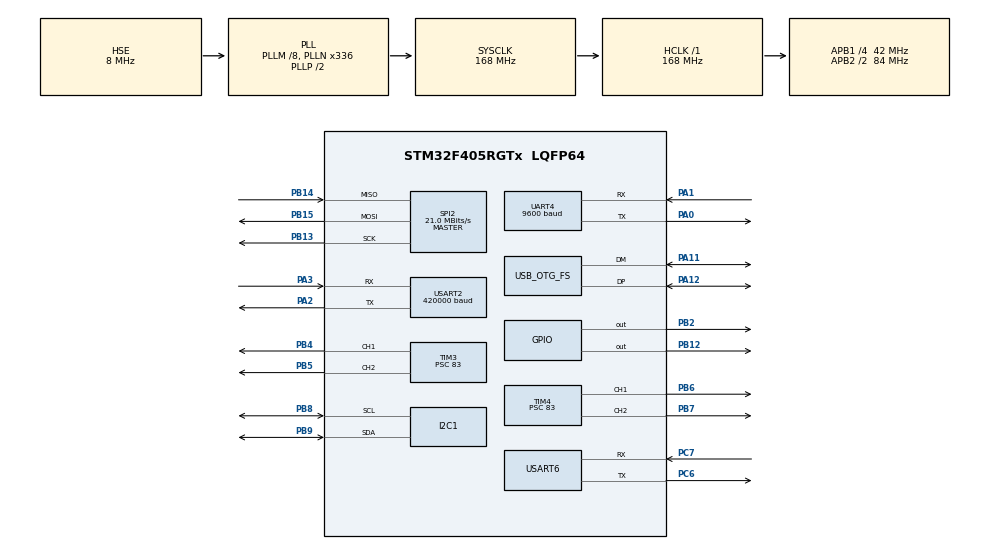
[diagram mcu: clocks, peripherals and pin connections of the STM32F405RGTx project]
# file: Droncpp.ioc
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Dma.Request0=UART4_TX
Dma.Request1=USART2_RX
Dma.Request2=USART2_TX
Dma.UART4_TX.0.Direction=DMA_MEMORY_TO_PERIPH
Dma.UART4_TX.0.FIFOMode=DMA_FIFOMODE_DISABLE
Dma.UART4_TX.0.Instance=DMA1_Stream4
Dma.UART4_TX.0.MemDataAlignment=DMA_MDATAALIGN_BYTE
Dma.UART4_TX.0.MemInc=DMA_MINC_ENABLE
Dma.UART4_TX.0.Mode=DMA_NORMAL
Dma.UART4_TX.0.PeriphDataAlignment=DMA_PDATAALIGN_BYTE
Dma.UART4_TX.0.PeriphInc=DMA_PINC_DISABLE
Dma.UART4_TX.0.Priority=DMA_PRIORITY_LOW
Dma.USART2_RX.1.Direction=DMA_PERIPH_TO_MEMORY
Dma.USART2_RX.1.FIFOMode=DMA_FIFOMODE_DISABLE
Dma.USART2_RX.1.Instance=DMA1_Stream5
Dma.USART2_RX.1.MemDataAlignment=DMA_MDATAALIGN_BYTE
Dma.USART2_RX.1.MemInc=DMA_MINC_ENABLE
Dma.USART2_RX.1.Mode=DMA_CIRCULAR
Dma.USART2_RX.1.PeriphDataAlignment=DMA_PDATAALIGN_BYTE
Dma.USART2_RX.1.PeriphInc=DMA_PINC_DISABLE
Dma.USART2_RX.1.Priority=DMA_PRIORITY_VERY_HIGH
Dma.USART2_TX.2.Direction=DMA_MEMORY_TO_PERIPH
Dma.USART2_TX.2.FIFOMode=DMA_FIFOMODE_DISABLE
Dma.USART2_TX.2.Instance=DMA1_Stream6
Dma.USART2_TX.2.MemDataAlignment=DMA_MDATAALIGN_BYTE
Dma.USART2_TX.2.MemInc=DMA_MINC_ENABLE
Dma.USART2_TX.2.Mode=DMA_CIRCULAR
Dma.USART2_TX.2.PeriphDataAlignment=DMA_PDATAALIGN_BYTE
Dma.USART2_TX.2.PeriphInc=DMA_PINC_DISABLE
Dma.USART2_TX.2.Priority=DMA_PRIORITY_VERY_HIGH
I2C1.I2C_Mode=I2C_Fast
Mcu.Family=STM32F4
Mcu.Name=STM32F405RGTx
Mcu.Package=LQFP64
NVIC.DMA1_Stream4_IRQn=true\:0\:0\:false\:false\:true\:false\:true\:true
NVIC.DMA1_Stream5_IRQn=true\:0\:0\:false\:false\:true\:false\:true\:true
NVIC.DMA1_Stream6_IRQn=true\:0\:0\:false\:false\:true\:false\:true\:true
NVIC.OTG_FS_IRQn=true\:0\:0\:false\:false\:true\:false\:true\:true
NVIC.PriorityGroup=NVIC_PRIORITYGROUP_4
NVIC.UART4_IRQn=true\:0\:0\:false\:false\:true\:true\:true\:true
NVIC.USART2_IRQn=true\:0\:0\:false\:false\:true\:true\:true\:true
NVIC.USART6_IRQn=true\:0\:0\:false\:false\:true\:true\:true\:true
PA0-WKUP.Mode=Asynchronous
PA0-WKUP.Signal=UART4_TX
PA1.Mode=Asynchronous
PA1.Signal=UART4_RX
PA11.Mode=Device_Only
PA11.Signal=USB_OTG_FS_DM
PA12.Mode=Device_Only
PA12.Signal=USB_OTG_FS_DP
PA13.Mode=Serial_Wire
PA13.Signal=SYS_JTMS-SWDIO
PA14.Mode=Serial_Wire
PA14.Signal=SYS_JTCK-SWCLK
PA2.Mode=Asynchronous
PA2.Signal=USART2_TX
PA3.Mode=Asynchronous
PA3.Signal=USART2_RX
PB12.Signal=GPIO_Output
PB13.Mode=Full_Duplex_Master
PB13.Signal=SPI2_SCK
PB14.Mode=Full_Duplex_Master
PB14.Signal=SPI2_MISO
PB15.Mode=Full_Duplex_Master
PB15.Signal=SPI2_MOSI
PB2.Signal=GPIO_Output
PB4.Signal=S_TIM3_CH1
PB5.Signal=S_TIM3_CH2
PB6.Signal=S_TIM4_CH1
PB7.Signal=S_TIM4_CH2
PB8.Mode=I2C
PB8.Signal=I2C1_SCL
PB9.Mode=I2C
PB9.Signal=I2C1_SDA
PC6.Mode=Asynchronous
PC6.Signal=USART6_TX
PC7.Mode=Asynchronous
PC7.Signal=USART6_RX
PH0-OSC_IN.Mode=HSE-External-Oscillator
PH0-OSC_IN.Signal=RCC_OSC_IN
PH1-OSC_OUT.Mode=HSE-External-Oscillator
PH1-OSC_OUT.Signal=RCC_OSC_OUT
ProjectManager.HeapSize=0x200
ProjectManager.StackSize=0x400
ProjectManager.TargetToolchain=STM32CubeIDE
RCC.48MHZClocksFreq_Value=48000000
RCC.AHBFreq_Value=168000000
RCC.APB1CLKDivider=RCC_HCLK_DIV4
RCC.APB1Freq_Value=42000000
RCC.APB1TimFreq_Value=84000000
RCC.APB2CLKDivider=RCC_HCLK_DIV2
RCC.APB2Freq_Value=84000000
RCC.APB2TimFreq_Value=168000000
RCC.CortexFreq_Value=168000000
RCC.HCLKFreq_Value=168000000
RCC.HSE_VALUE=8000000
RCC.HSI_VALUE=16000000
RCC.LSE_VALUE=32768
RCC.PLLM=8
RCC.PLLN=336
RCC.PLLQ=7
RCC.SYSCLKFreq_VALUE=168000000
RCC.SYSCLKSource=RCC_SYSCLKSOURCE_PLLCLK
RCC.VCOOutputFreq_Value=336000000
SH.S_TIM3_CH1.0=TIM3_CH1,PWM Generation1 CH1
SH.S_TIM3_CH2.0=TIM3_CH2,PWM Generation2 CH2
SH.S_TIM4_CH1.0=TIM4_CH1,PWM Generation1 CH1
SH.S_TIM4_CH2.0=TIM4_CH2,PWM Generation2 CH2
SPI2.BaudRatePrescaler=SPI_BAUDRATEPRESCALER_2
SPI2.CalculateBaudRate=21.0 MBits/s
SPI2.Direction=SPI_DIRECTION_2LINES
SPI2.Mode=SPI_MODE_MASTER
SPI2.VirtualType=VM_MASTER
TIM3.Channel-PWM\ Generation1\ CH1=TIM_CHANNEL_1
TIM3.Channel-PWM\ Generation2\ CH2=TIM_CHANNEL_2
TIM3.OC1Preload_PWM=DISABLE
TIM3.OC2Preload_PWM=DISABLE
TIM3.OCMode_PWM-PWM\ Generation1\ CH1=TIM_OCMODE_PWM1
TIM3.OCMode_PWM-PWM\ Generation2\ CH2=TIM_OCMODE_PWM1
TIM3.OCPolarity_1=TIM_OCPOLARITY_HIGH
TIM3.OCPolarity_2=TIM_OCPOLARITY_HIGH
TIM3.Period=19999
TIM3.Prescaler=83
TIM4.Channel-PWM\ Generation1\ CH1=TIM_CHANNEL_1
TIM4.Channel-PWM\ Generation2\ CH2=TIM_CHANNEL_2
TIM4.OC1Preload_PWM=DISABLE
TIM4.OC2Preload_PWM=DISABLE
TIM4.OCPolarity_1=TIM_OCPOLARITY_HIGH
TIM4.OCPolarity_2=TIM_OCPOLARITY_HIGH
TIM4.Period=19999
TIM4.Prescaler=83
UART4.BaudRate=9600
UART4.VirtualMode=Asynchronous
USART2.BaudRate=420000
USART2.VirtualMode=VM_ASYNC
USART6.VirtualMode=VM_ASYNC
USB_DEVICE.CLASS_NAME_FS=CDC
USB_DEVICE.VirtualMode-CDC_FS=Cdc
USB_DEVICE.VirtualModeFS=Cdc_FS
USB_OTG_FS.VirtualMode=Device_Only
VP_TIM3_VS_ClockSourceINT.Mode=Internal
VP_TIM4_VS_ClockSourceINT.Mode=Internal
VP_USB_DEVICE_VS_USB_DEVICE_CDC_FS.Mode=CDC_FS
board=custom

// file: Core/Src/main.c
/* USER CODE BEGIN Header */
/**
  ******************************************************************************
  * @file           : main.c
  * @brief          : Main program body
  ******************************************************************************
  * @attention
  *
  * Copyright (c) 2026 STMicroelectronics.
  * All rights reserved.
  *
  * This software is licensed under terms that can be found in the LICENSE file
  * in the root directory of this software component.
  * If no LICENSE file comes with this software, it is provided AS-IS.
  *
  ******************************************************************************
  */
/* USER CODE END Header */
#include "main.h"
#include "usb_device.h"

/* USER CODE BEGIN Includes */
#include "usbd_cdc_if.h"
//#include "mpu6500.hpp"
//#include "qmc5883p.hpp"
//#include "gnss.hpp"
//#include "mtf02.hpp"
//#include "crsf.hpp"
#include "puente.h"
/* USER CODE END Includes */

I2C_HandleTypeDef hi2c1;

SPI_HandleTypeDef hspi2;

TIM_HandleTypeDef htim3;
TIM_HandleTypeDef htim4;

UART_HandleTypeDef huart4;
UART_HandleTypeDef huart2;
UART_HandleTypeDef huart6;
DMA_HandleTypeDef hdma_uart4_tx;
DMA_HandleTypeDef hdma_usart2_rx;
DMA_HandleTypeDef hdma_usart2_tx;

/* USER CODE BEGIN PV */
//static MPU6500 imu(&hspi2);
//static QMC5883 mag(&hi2c1);
//static Gnss gps(&huart4);
//static MTF01 flow(&huart6);
//static CRSF_Radio radioData;
//static CRSF radio(&huart2);
/* USER CODE END PV */

void SystemClock_Config(void);
static void MX_GPIO_Init(void);
static void MX_DMA_Init(void);
static void MX_SPI2_Init(void);
static void MX_I2C1_Init(void);
static void MX_UART4_Init(void);
static void MX_USART6_UART_Init(void);
static void MX_USART2_UART_Init(void);
static void MX_TIM3_Init(void);
static void MX_TIM4_Init(void);

int main(void)
{

  /* MCU Configuration--------------------------------------------------------*/

  /* Reset of all peripherals, Initializes the Flash interface and the Systick. */
  HAL_Init();

  /* Configure the system clock */
  SystemClock_Config();

  /* Initialize all configured peripherals */
  MX_GPIO_Init();
  MX_DMA_Init();
  MX_SPI2_Init();
  MX_USB_DEVICE_Init();
  MX_I2C1_Init();
  MX_UART4_Init();
  MX_USART6_UART_Init();
  MX_USART2_UART_Init();
  MX_TIM3_Init();
  MX_TIM4_Init();
  /* USER CODE BEGIN 2 */
  //imu.Init();
  //imu.CalibrateGyro();
  //imu.CalibrateAccel();
  //mag.Init();
  //gps.Init();
  //gps.SetMode(GnssMode::Stationary);
  //HAL_Delay(250);
  //flow.Init();
  //radio.Init(&radioData);

  HAL_TIM_PWM_Start(&htim3, TIM_CHANNEL_1);
  HAL_TIM_PWM_Start(&htim3, TIM_CHANNEL_2);
  HAL_TIM_PWM_Start(&htim4, TIM_CHANNEL_1);
  HAL_TIM_PWM_Start(&htim4, TIM_CHANNEL_2);

  //__HAL_TIM_SET_COMPARE(&htim3, TIM_CHANNEL_1, 1900);
  //__HAL_TIM_SET_COMPARE(&htim3, TIM_CHANNEL_2, 1900);
  //__HAL_TIM_SET_COMPARE(&htim4, TIM_CHANNEL_1, 1900);
  //__HAL_TIM_SET_COMPARE(&htim4, TIM_CHANNEL_2, 1900);
  //HAL_Delay(3000);
  __HAL_TIM_SET_COMPARE(&htim3, TIM_CHANNEL_1, 1100);
  __HAL_TIM_SET_COMPARE(&htim3, TIM_CHANNEL_2, 1100);
  __HAL_TIM_SET_COMPARE(&htim4, TIM_CHANNEL_1, 1100);
  __HAL_TIM_SET_COMPARE(&htim4, TIM_CHANNEL_2, 1100);

  //App_Init();

  /* USER CODE END 2 */

  /* Infinite loop */
  while (1)
  {

    /* USER CODE BEGIN 3 */
	  //App_Loop();
	  	  /*imu.Process();
	      const MPU6500_Data &d = imu.GetData();

	      static char msg[150];    imu.Process();
    mag.Process();
    mag.ComputeHeading(imu.GetData().roll, imu.GetData().pitch);
    radio.Process();

    static uint32_t lastGpsUpdate = 0;
    if(HAL_GetTick() - lastGpsUpdate >= 200)
    {
        lastGpsUpdate = HAL_GetTick();
        gps.Update();
        // impresión...
    }
    // resto de la lógica de impresión...
	      int len = snprintf(msg, sizeof(msg),"AX:%.2f AY:%.2f AZ:%.2f\r\n"
											  "GX:%.2f GY:%.2f GZ:%.2f \r\n"
	    		  	  	  	  	  	  	  	  "Roll:%.2f Pitch:%.2f\r\n",
											  d.ax, d.ay, d.az, d.gx, d.gy, d.gz, d.roll, d.pitch);

	      CDC_Transmit_FS((uint8_t*)msg, len);
	      HAL_Delay(100);
	      mag.Process();         // usa el roll/pitch fresco del gyro
	      mag.ComputeHeading(imu.GetData().roll, imu.GetData().pitch);   // calcula heading aparte

	      const QMC5883Data &d = mag.GetData();

	      static char msg[100];
	      int len = snprintf(msg, sizeof(msg),
	          "MX:%.2f MY:%.2f MZ:%.2f Heading:%.2f\r\n",
	          d.mx, d.my, d.mz, d.heading);

	      CDC_Transmit_FS((uint8_t*)msg, len);
	      HAL_Delay(100);
	      static uint32_t lastGpsUpdate = 0;
	          if(HAL_GetTick() - lastGpsUpdate >= 200)
	          {
	              lastGpsUpdate = HAL_GetTick();
	              gps.Update();

	              const GnssData &d = gps.GetData();
	              static char msg[300];
	              int len = snprintf(msg, sizeof(msg),
	                  "GPS\r\n"
	                  "Day: %d-%d-%d\r\n"
	                  "Time: %d:%d:%d\r\n"
	                  "Status of fix: %d\r\n"
	                  "Sat used: %d  Sat count: %d\r\n"
	                  "Lat: %f  Lon: %f\r\n"
	                  "Height ellip.(m): %f  Height MSL(m): %f\r\n"
	                  "Ground Speed(2D): %ld\r\n",
	                  d.day, d.month, d.year,
	                  d.hour, d.min, d.sec,
	                  d.fixType,
	                  d.numSV, d.satCount,
	                  d.fLat, d.fLon,
	                  static_cast<float>(d.height) / 1000.0f,
	                  static_cast<float>(d.hMSL) / 1000.0f,
	                  d.gSpeed);
	              CDC_Transmit_FS((uint8_t*)msg, len);
	          }
	      const MTF01_Data &d = flow.GetData();

	      static uint32_t lastFlowUpdate = 0;
	      if(HAL_GetTick() - lastFlowUpdate >= 100)
	      {
	          lastFlowUpdate = HAL_GetTick();

	          static char msg[150];
	          int len = snprintf(msg, sizeof(msg),
	              "FLOW\r\n"
	              "Distance: %.2f mm\r\n"
	              "FlowX: %.2f  FlowY: %.2f\r\n"
	              "Quality: %d  Status: %d\r\n",
	              d.distance, d.flowX, d.flowY,
	              d.quality, d.status);

	          CDC_Transmit_FS((uint8_t*)msg, len);
	      }
	      radio.Process();

	      if(radio.NewFrameAvailable() || true)  // o simplemente lee cuando quieras
	      {
	          static char msg[200];
	          int len = snprintf(msg, sizeof(msg),
	              "CRSF status=%d activeChannels=%d\r\n"
	              "CH1:%d CH2:%d CH3:%d CH4:%d\r\n",
	              radioData.status, radioData.activeChannels,
	              radioData.ch[0], radioData.ch[1], radioData.ch[2], radioData.ch[3]);
	          CDC_Transmit_FS((uint8_t*)msg, len);
	      }*/
  }
  /* USER CODE END 3 */
}

void SystemClock_Config(void)
{
  RCC_OscInitTypeDef RCC_OscInitStruct = {0};
  RCC_ClkInitTypeDef RCC_ClkInitStruct = {0};

  /** Configure the main internal regulator output voltage
  */
  __HAL_RCC_PWR_CLK_ENABLE();
  __HAL_PWR_VOLTAGESCALING_CONFIG(PWR_REGULATOR_VOLTAGE_SCALE1);

  /** Initializes the RCC Oscillators according to the specified parameters
  * in the RCC_OscInitTypeDef structure.
  */
  RCC_OscInitStruct.OscillatorType = RCC_OSCILLATORTYPE_HSE;
  RCC_OscInitStruct.HSEState = RCC_HSE_ON;
  RCC_OscInitStruct.PLL.PLLState = RCC_PLL_ON;
  RCC_OscInitStruct.PLL.PLLSource = RCC_PLLSOURCE_HSE;
  RCC_OscInitStruct.PLL.PLLM = 8;
  RCC_OscInitStruct.PLL.PLLN = 336;
  RCC_OscInitStruct.PLL.PLLP = RCC_PLLP_DIV2;
  RCC_OscInitStruct.PLL.PLLQ = 7;
  if (HAL_RCC_OscConfig(&RCC_OscInitStruct) != HAL_OK)
  {
    Error_Handler();
  }

  /** Initializes the CPU, AHB and APB buses clocks
  */
  RCC_ClkInitStruct.ClockType = RCC_CLOCKTYPE_HCLK|RCC_CLOCKTYPE_SYSCLK
                              |RCC_CLOCKTYPE_PCLK1|RCC_CLOCKTYPE_PCLK2;
  RCC_ClkInitStruct.SYSCLKSource = RCC_SYSCLKSOURCE_PLLCLK;
  RCC_ClkInitStruct.AHBCLKDivider = RCC_SYSCLK_DIV1;
  RCC_ClkInitStruct.APB1CLKDivider = RCC_HCLK_DIV4;
  RCC_ClkInitStruct.APB2CLKDivider = RCC_HCLK_DIV2;

  if (HAL_RCC_ClockConfig(&RCC_ClkInitStruct, FLASH_LATENCY_5) != HAL_OK)
  {
    Error_Handler();
  }
}

static void MX_I2C1_Init(void)
{

  hi2c1.Instance = I2C1;
  hi2c1.Init.ClockSpeed = 400000;
  hi2c1.Init.DutyCycle = I2C_DUTYCYCLE_2;
  hi2c1.Init.OwnAddress1 = 0;
  hi2c1.Init.AddressingMode = I2C_ADDRESSINGMODE_7BIT;
  hi2c1.Init.DualAddressMode = I2C_DUALADDRESS_DISABLE;
  hi2c1.Init.OwnAddress2 = 0;
  hi2c1.Init.GeneralCallMode = I2C_GENERALCALL_DISABLE;
  hi2c1.Init.NoStretchMode = I2C_NOSTRETCH_DISABLE;
  if (HAL_I2C_Init(&hi2c1) != HAL_OK)
  {
    Error_Handler();
  }

}

static void MX_SPI2_Init(void)
{

  /* SPI2 parameter configuration*/
  hspi2.Instance = SPI2;
  hspi2.Init.Mode = SPI_MODE_MASTER;
  hspi2.Init.Direction = SPI_DIRECTION_2LINES;
  hspi2.Init.DataSize = SPI_DATASIZE_8BIT;
  hspi2.Init.CLKPolarity = SPI_POLARITY_LOW;
  hspi2.Init.CLKPhase = SPI_PHASE_1EDGE;
  hspi2.Init.NSS = SPI_NSS_SOFT;
  hspi2.Init.BaudRatePrescaler = SPI_BAUDRATEPRESCALER_2;
  hspi2.Init.FirstBit = SPI_FIRSTBIT_MSB;
  hspi2.Init.TIMode = SPI_TIMODE_DISABLE;
  hspi2.Init.CRCCalculation = SPI_CRCCALCULATION_DISABLE;
  hspi2.Init.CRCPolynomial = 10;
  if (HAL_SPI_Init(&hspi2) != HAL_OK)
  {
    Error_Handler();
  }

}

static void MX_TIM3_Init(void)
{

  TIM_ClockConfigTypeDef sClockSourceConfig = {0};
  TIM_MasterConfigTypeDef sMasterConfig = {0};
  TIM_OC_InitTypeDef sConfigOC = {0};

  htim3.Instance = TIM3;
  htim3.Init.Prescaler = 83;
  htim3.Init.CounterMode = TIM_COUNTERMODE_UP;
  htim3.Init.Period = 19999;
  htim3.Init.ClockDivision = TIM_CLOCKDIVISION_DIV1;
  htim3.Init.AutoReloadPreload = TIM_AUTORELOAD_PRELOAD_DISABLE;
  if (HAL_TIM_Base_Init(&htim3) != HAL_OK)
  {
    Error_Handler();
  }
  sClockSourceConfig.ClockSource = TIM_CLOCKSOURCE_INTERNAL;
  if (HAL_TIM_ConfigClockSource(&htim3, &sClockSourceConfig) != HAL_OK)
  {
    Error_Handler();
  }
  if (HAL_TIM_PWM_Init(&htim3) != HAL_OK)
  {
    Error_Handler();
  }
  sMasterConfig.MasterOutputTrigger = TIM_TRGO_RESET;
  sMasterConfig.MasterSlaveMode = TIM_MASTERSLAVEMODE_DISABLE;
  if (HAL_TIMEx_MasterConfigSynchronization(&htim3, &sMasterConfig) != HAL_OK)
  {
    Error_Handler();
  }
  sConfigOC.OCMode = TIM_OCMODE_PWM1;
  sConfigOC.Pulse = 0;
  sConfigOC.OCPolarity = TIM_OCPOLARITY_HIGH;
  sConfigOC.OCFastMode = TIM_OCFAST_DISABLE;
  if (HAL_TIM_PWM_ConfigChannel(&htim3, &sConfigOC, TIM_CHANNEL_1) != HAL_OK)
  {
    Error_Handler();
  }
  __HAL_TIM_DISABLE_OCxPRELOAD(&htim3, TIM_CHANNEL_1);
  if (HAL_TIM_PWM_ConfigChannel(&htim3, &sConfigOC, TIM_CHANNEL_2) != HAL_OK)
  {
    Error_Handler();
  }
  __HAL_TIM_DISABLE_OCxPRELOAD(&htim3, TIM_CHANNEL_2);
  HAL_TIM_MspPostInit(&htim3);

}

static void MX_TIM4_Init(void)
{

  TIM_ClockConfigTypeDef sClockSourceConfig = {0};
  TIM_MasterConfigTypeDef sMasterConfig = {0};
  TIM_OC_InitTypeDef sConfigOC = {0};

  htim4.Instance = TIM4;
  htim4.Init.Prescaler = 83;
  htim4.Init.CounterMode = TIM_COUNTERMODE_UP;
  htim4.Init.Period = 19999;
  htim4.Init.ClockDivision = TIM_CLOCKDIVISION_DIV1;
  htim4.Init.AutoReloadPreload = TIM_AUTORELOAD_PRELOAD_DISABLE;
  if (HAL_TIM_Base_Init(&htim4) != HAL_OK)
  {
    Error_Handler();
  }
  sClockSourceConfig.ClockSource = TIM_CLOCKSOURCE_INTERNAL;
  if (HAL_TIM_ConfigClockSource(&htim4, &sClockSourceConfig) != HAL_OK)
  {
    Error_Handler();
  }
  if (HAL_TIM_PWM_Init(&htim4) != HAL_OK)
  {
    Error_Handler();
  }
  sMasterConfig.MasterOutputTrigger = TIM_TRGO_RESET;
  sMasterConfig.MasterSlaveMode = TIM_MASTERSLAVEMODE_DISABLE;
  if (HAL_TIMEx_MasterConfigSynchronization(&htim4, &sMasterConfig) != HAL_OK)
  {
    Error_Handler();
  }
  sConfigOC.OCMode = TIM_OCMODE_PWM1;
  sConfigOC.Pulse = 0;
  sConfigOC.OCPolarity = TIM_OCPOLARITY_HIGH;
  sConfigOC.OCFastMode = TIM_OCFAST_DISABLE;
  if (HAL_TIM_PWM_ConfigChannel(&htim4, &sConfigOC, TIM_CHANNEL_1) != HAL_OK)
  {
    Error_Handler();
  }
  __HAL_TIM_DISABLE_OCxPRELOAD(&htim4, TIM_CHANNEL_1);
  if (HAL_TIM_PWM_ConfigChannel(&htim4, &sConfigOC, TIM_CHANNEL_2) != HAL_OK)
  {
    Error_Handler();
  }
  __HAL_TIM_DISABLE_OCxPRELOAD(&htim4, TIM_CHANNEL_2);
  HAL_TIM_MspPostInit(&htim4);

}

static void MX_UART4_Init(void)
{

  huart4.Instance = UART4;
  huart4.Init.BaudRate = 9600;
  huart4.Init.WordLength = UART_WORDLENGTH_8B;
  huart4.Init.StopBits = UART_STOPBITS_1;
  huart4.Init.Parity = UART_PARITY_NONE;
  huart4.Init.Mode = UART_MODE_TX_RX;
  huart4.Init.HwFlowCtl = UART_HWCONTROL_NONE;
  huart4.Init.OverSampling = UART_OVERSAMPLING_16;
  if (HAL_UART_Init(&huart4) != HAL_OK)
  {
    Error_Handler();
  }

}

static void MX_USART2_UART_Init(void)
{

  huart2.Instance = USART2;
  huart2.Init.BaudRate = 420000;
  huart2.Init.WordLength = UART_WORDLENGTH_8B;
  huart2.Init.StopBits = UART_STOPBITS_1;
  huart2.Init.Parity = UART_PARITY_NONE;
  huart2.Init.Mode = UART_MODE_TX_RX;
  huart2.Init.HwFlowCtl = UART_HWCONTROL_NONE;
  huart2.Init.OverSampling = UART_OVERSAMPLING_16;
  if (HAL_UART_Init(&huart2) != HAL_OK)
  {
    Error_Handler();
  }

}

static void MX_USART6_UART_Init(void)
{

  huart6.Instance = USART6;
  huart6.Init.BaudRate = 115200;
  huart6.Init.WordLength = UART_WORDLENGTH_8B;
  huart6.Init.StopBits = UART_STOPBITS_1;
  huart6.Init.Parity = UART_PARITY_NONE;
  huart6.Init.Mode = UART_MODE_TX_RX;
  huart6.Init.HwFlowCtl = UART_HWCONTROL_NONE;
  huart6.Init.OverSampling = UART_OVERSAMPLING_16;
  if (HAL_UART_Init(&huart6) != HAL_OK)
  {
    Error_Handler();
  }

}

static void MX_DMA_Init(void)
{

  /* DMA controller clock enable */
  __HAL_RCC_DMA1_CLK_ENABLE();

  /* DMA interrupt init */
  /* DMA1_Stream4_IRQn interrupt configuration */
  HAL_NVIC_SetPriority(DMA1_Stream4_IRQn, 0, 0);
  HAL_NVIC_EnableIRQ(DMA1_Stream4_IRQn);
  /* DMA1_Stream5_IRQn interrupt configuration */
  HAL_NVIC_SetPriority(DMA1_Stream5_IRQn, 0, 0);
  HAL_NVIC_EnableIRQ(DMA1_Stream5_IRQn);
  /* DMA1_Stream6_IRQn interrupt configuration */
  HAL_NVIC_SetPriority(DMA1_Stream6_IRQn, 0, 0);
  HAL_NVIC_EnableIRQ(DMA1_Stream6_IRQn);

}

static void MX_GPIO_Init(void)
{
  GPIO_InitTypeDef GPIO_InitStruct = {0};

  /* GPIO Ports Clock Enable */
  __HAL_RCC_GPIOH_CLK_ENABLE();
  __HAL_RCC_GPIOA_CLK_ENABLE();
  __HAL_RCC_GPIOB_CLK_ENABLE();
  __HAL_RCC_GPIOC_CLK_ENABLE();

  /*Configure GPIO pin Output Level */
  HAL_GPIO_WritePin(GPIOB, GPIO_PIN_2|GPIO_PIN_12, GPIO_PIN_RESET);

  /*Configure GPIO pins : PB2 PB12 */
  GPIO_InitStruct.Pin = GPIO_PIN_2|GPIO_PIN_12;
  GPIO_InitStruct.Mode = GPIO_MODE_OUTPUT_PP;
  GPIO_InitStruct.Pull = GPIO_NOPULL;
  GPIO_InitStruct.Speed = GPIO_SPEED_FREQ_LOW;
  HAL_GPIO_Init(GPIOB, &GPIO_InitStruct);

}

void Error_Handler(void)
{
  __disable_irq();
  while (1)
  {
  }
}
